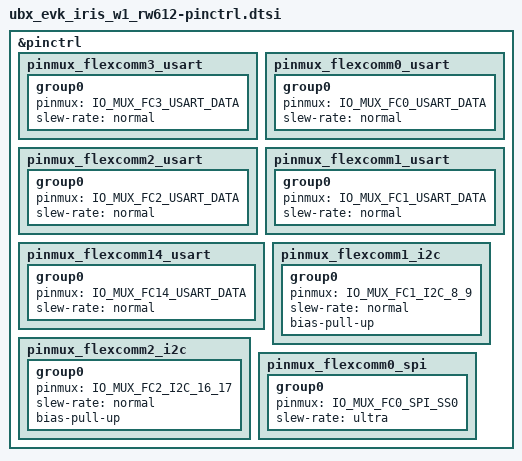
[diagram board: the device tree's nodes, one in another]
/*
 * Copyright (c) 2025 u-blox AG
 *
 * SPDX-License-Identifier: Apache-2.0
 */

#include <nxp/rw/RW612-pinctrl.h>

&pinctrl {

	//default-UART

	pinmux_flexcomm3_usart: pinmux_flexcomm3_usart {
		group0 {
			pinmux = <IO_MUX_FC3_USART_DATA>;
			slew-rate = "normal";
		};
	};

	// FCx all default configure as a UART

	pinmux_flexcomm0_usart: pinmux_flexcomm0_usart {
		group0 {
			pinmux = <IO_MUX_FC0_USART_DATA>;
			slew-rate = "normal";
		};
	};

	pinmux_flexcomm2_usart: pinmux_flexcomm2_usart {
		group0 {
			pinmux = <IO_MUX_FC2_USART_DATA>;
			slew-rate = "normal";
		};
	};

	pinmux_flexcomm1_usart: pinmux_flexcomm1_usart {
		group0 {
			pinmux = <IO_MUX_FC1_USART_DATA>;
			slew-rate = "normal";
		};
	};

	pinmux_flexcomm14_usart: pinmux_flexcomm14_usart {
		group0 {
			pinmux = <IO_MUX_FC14_USART_DATA>;
			slew-rate = "normal";
		};
	};

// i2c

	pinmux_flexcomm1_i2c: pinmux_flexcomm1_i2c {
		group0 {
			pinmux = <IO_MUX_FC1_I2C_8_9>;
			slew-rate = "normal";
			bias-pull-up;
		};
	};

	pinmux_flexcomm2_i2c: pinmux_flexcomm2_i2c {
		group0 {
			pinmux = <IO_MUX_FC2_I2C_16_17>;
			slew-rate = "normal";
			bias-pull-up;
		};
	};


//spi

	pinmux_flexcomm0_spi: pinmux_flexcomm0_spi {
		group0 {
			pinmux = <IO_MUX_FC0_SPI_SS0>;
			slew-rate = "ultra";
		};
	};
};
